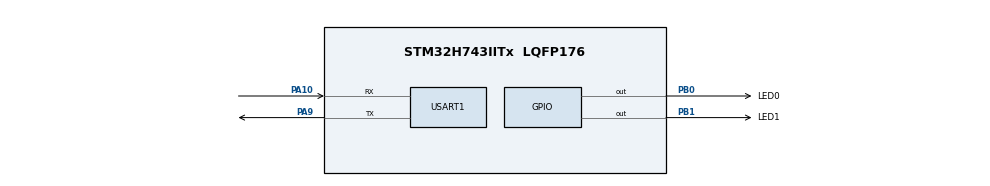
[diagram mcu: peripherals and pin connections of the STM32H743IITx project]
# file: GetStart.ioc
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Dma.Request0=USART1_TX
Dma.USART1_TX.0.Direction=DMA_MEMORY_TO_PERIPH
Dma.USART1_TX.0.EventEnable=DISABLE
Dma.USART1_TX.0.FIFOMode=DMA_FIFOMODE_DISABLE
Dma.USART1_TX.0.Instance=DMA1_Stream0
Dma.USART1_TX.0.MemDataAlignment=DMA_MDATAALIGN_BYTE
Dma.USART1_TX.0.MemInc=DMA_MINC_ENABLE
Dma.USART1_TX.0.Mode=DMA_NORMAL
Dma.USART1_TX.0.PeriphDataAlignment=DMA_PDATAALIGN_BYTE
Dma.USART1_TX.0.PeriphInc=DMA_PINC_DISABLE
Dma.USART1_TX.0.Polarity=HAL_DMAMUX_REQ_GEN_RISING
Dma.USART1_TX.0.Priority=DMA_PRIORITY_LOW
Dma.USART1_TX.0.RequestNumber=1
Dma.USART1_TX.0.SignalID=NONE
Dma.USART1_TX.0.SyncEnable=DISABLE
Dma.USART1_TX.0.SyncPolarity=HAL_DMAMUX_SYNC_NO_EVENT
Dma.USART1_TX.0.SyncRequestNumber=1
Dma.USART1_TX.0.SyncSignalID=NONE
Mcu.Family=STM32H7
Mcu.Name=STM32H743IITx
Mcu.Package=LQFP176
NVIC.DMA1_Stream0_IRQn=true\:0\:0\:false\:false\:true\:false\:true
NVIC.PriorityGroup=NVIC_PRIORITYGROUP_4
NVIC.USART1_IRQn=true\:0\:0\:false\:false\:true\:true\:true
PA10.Mode=Asynchronous
PA10.Signal=USART1_RX
PA13\ (JTMS/SWDIO).Mode=Serial_Wire
PA13\ (JTMS/SWDIO).Signal=DEBUG_JTMS-SWDIO
PA14\ (JTCK/SWCLK).Mode=Serial_Wire
PA14\ (JTCK/SWCLK).Signal=DEBUG_JTCK-SWCLK
PA9.Mode=Asynchronous
PA9.Signal=USART1_TX
PB0.GPIO_Label=LED0
PB0.PinState=GPIO_PIN_RESET
PB0.Signal=GPIO_Output
PB1.GPIO_Label=LED1
PB1.Signal=GPIO_Output
PC14-OSC32_IN\ (OSC32_IN).Mode=LSE-External-Oscillator
PC14-OSC32_IN\ (OSC32_IN).Signal=RCC_OSC32_IN
PC15-OSC32_OUT\ (OSC32_OUT).Mode=LSE-External-Oscillator
PC15-OSC32_OUT\ (OSC32_OUT).Signal=RCC_OSC32_OUT
PH0-OSC_IN\ (PH0).Mode=HSE-External-Oscillator
PH0-OSC_IN\ (PH0).Signal=RCC_OSC_IN
PH1-OSC_OUT\ (PH1).Mode=HSE-External-Oscillator
PH1-OSC_OUT\ (PH1).Signal=RCC_OSC_OUT
ProjectManager.HeapSize=0x200
ProjectManager.StackSize=0x400
ProjectManager.TargetToolchain=Makefile
RCC.ADCFreq_Value=16125000
RCC.APB1Freq_Value=120000000
RCC.APB2Freq_Value=120000000
RCC.APB3Freq_Value=120000000
RCC.APB4Freq_Value=120000000
RCC.CortexFreq_Value=480000000
RCC.D1PPRE=RCC_APB3_DIV2
RCC.D2PPRE1=RCC_APB1_DIV2
RCC.D2PPRE2=RCC_APB2_DIV2
RCC.D3PPRE=RCC_APB4_DIV2
RCC.DIVM1=1
RCC.DIVN1=120
RCC.HCLKFreq_Value=240000000
RCC.HPRE=RCC_HCLK_DIV2
RCC.HSE_VALUE=8000000
RCC.PLL2FRACN=0
RCC.PLL3FRACN=0
RCC.PLLFRACN=0
RCC.PLLSourceVirtual=RCC_PLLSOURCE_HSE
RCC.SYSCLKFreq_VALUE=480000000
RCC.SYSCLKSource=RCC_SYSCLKSOURCE_PLLCLK
RCC.USBFreq_Value=480000000
USART1.VirtualMode-Asynchronous=VM_ASYNC
board=custom

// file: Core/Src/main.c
/* USER CODE BEGIN Header */
/**
  ******************************************************************************
  * @file           : main.c
  * @brief          : Main program body
  ******************************************************************************
  * @attention
  *
  * <h2><center>&copy; Copyright (c) 2021 STMicroelectronics.
  * All rights reserved.</center></h2>
  *
  * This software component is licensed by ST under BSD 3-Clause license,
  * the "License"; You may not use this file except in compliance with the
  * License. You may obtain a copy of the License at:
  *                        opensource.org/licenses/BSD-3-Clause
  *
  ******************************************************************************
  */
/* USER CODE END Header */
#include "main.h"
#include "dma.h"
#include "usart.h"
#include "gpio.h"

void SystemClock_Config(void);

int main(void)
{

  /* MCU Configuration--------------------------------------------------------*/

  /* Reset of all peripherals, Initializes the Flash interface and the Systick. */
  HAL_Init();

  /* Configure the system clock */
  SystemClock_Config();

  /* Initialize all configured peripherals */
  MX_GPIO_Init();
  MX_DMA_Init();
  MX_USART1_UART_Init();
  /* USER CODE BEGIN 2 */
  uint8_t dat[] = "Hello, I am Mculover666\r\n";
  /* USER CODE END 2 */

  /* Infinite loop */
  while (1)
  {

    /* USER CODE BEGIN 3 */
    //HAL_UART_Transmit(&huart1, "test\r\n", 6,0xfff);
    printf("hello world\r\n");
    HAL_GPIO_TogglePin(LED0_GPIO_Port,LED0_Pin);
    HAL_GPIO_TogglePin(LED1_GPIO_Port,LED1_Pin);
    HAL_Delay(1000);

  }
  /* USER CODE END 3 */
}

void SystemClock_Config(void)
{
  RCC_OscInitTypeDef RCC_OscInitStruct = {0};
  RCC_ClkInitTypeDef RCC_ClkInitStruct = {0};

  /** Supply configuration update enable
  */
  HAL_PWREx_ConfigSupply(PWR_LDO_SUPPLY);
  /** Configure the main internal regulator output voltage
  */
  __HAL_PWR_VOLTAGESCALING_CONFIG(PWR_REGULATOR_VOLTAGE_SCALE0);

  while(!__HAL_PWR_GET_FLAG(PWR_FLAG_VOSRDY)) {}
  /** Initializes the RCC Oscillators according to the specified parameters
  * in the RCC_OscInitTypeDef structure.
  */
  RCC_OscInitStruct.OscillatorType = RCC_OSCILLATORTYPE_HSE;
  RCC_OscInitStruct.HSEState = RCC_HSE_ON;
  RCC_OscInitStruct.PLL.PLLState = RCC_PLL_ON;
  RCC_OscInitStruct.PLL.PLLSource = RCC_PLLSOURCE_HSE;
  RCC_OscInitStruct.PLL.PLLM = 1;
  RCC_OscInitStruct.PLL.PLLN = 120;
  RCC_OscInitStruct.PLL.PLLP = 2;
  RCC_OscInitStruct.PLL.PLLQ = 2;
  RCC_OscInitStruct.PLL.PLLR = 2;
  RCC_OscInitStruct.PLL.PLLRGE = RCC_PLL1VCIRANGE_3;
  RCC_OscInitStruct.PLL.PLLVCOSEL = RCC_PLL1VCOWIDE;
  RCC_OscInitStruct.PLL.PLLFRACN = 0;
  if (HAL_RCC_OscConfig(&RCC_OscInitStruct) != HAL_OK)
  {
    Error_Handler();
  }
  /** Initializes the CPU, AHB and APB buses clocks
  */
  RCC_ClkInitStruct.ClockType = RCC_CLOCKTYPE_HCLK|RCC_CLOCKTYPE_SYSCLK
                              |RCC_CLOCKTYPE_PCLK1|RCC_CLOCKTYPE_PCLK2
                              |RCC_CLOCKTYPE_D3PCLK1|RCC_CLOCKTYPE_D1PCLK1;
  RCC_ClkInitStruct.SYSCLKSource = RCC_SYSCLKSOURCE_PLLCLK;
  RCC_ClkInitStruct.SYSCLKDivider = RCC_SYSCLK_DIV1;
  RCC_ClkInitStruct.AHBCLKDivider = RCC_HCLK_DIV2;
  RCC_ClkInitStruct.APB3CLKDivider = RCC_APB3_DIV2;
  RCC_ClkInitStruct.APB1CLKDivider = RCC_APB1_DIV2;
  RCC_ClkInitStruct.APB2CLKDivider = RCC_APB2_DIV2;
  RCC_ClkInitStruct.APB4CLKDivider = RCC_APB4_DIV2;

  if (HAL_RCC_ClockConfig(&RCC_ClkInitStruct, FLASH_LATENCY_4) != HAL_OK)
  {
    Error_Handler();
  }
}

void Error_Handler(void)
{
  __disable_irq();
  while (1)
  {
  }
}

/************************ (C) COPYRIGHT STMicroelectronics *****END OF FILE****/
